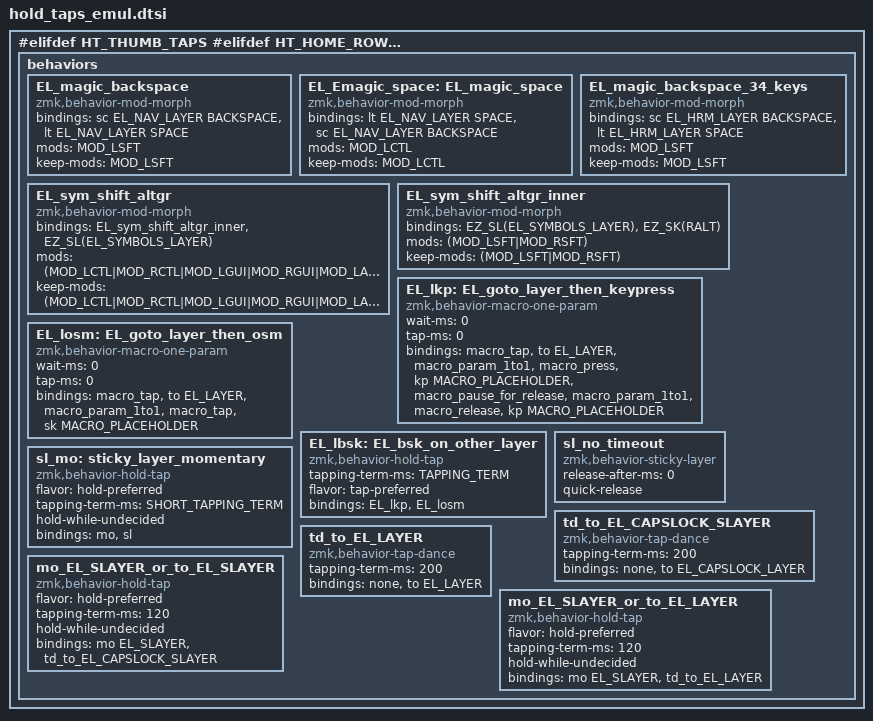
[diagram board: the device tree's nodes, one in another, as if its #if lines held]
#include <behaviors.dtsi>
#include <dt-bindings/zmk/keys.h>

// clang-format off
#define EL_LAYER           8
#define EL_CAPSLOCK_LAYER  9
#define EL_SLAYER         10
#define EL_1DK_LAYER      11
#define EL_S1DK_LAYER     12
#define EL_NUM_LOCK_LAYER 13
#define EL_SYMBOLS_LAYER  14
#define EL_SSYMBOLS_LAYER 15
#define EL_VIM_NAV_LAYER  16
#define EL_NUM_NAV_LAYER  17
#define EL_SNUM_NAV_LAYER 18
#define EL_NUM_ROW_LAYER  19

#define GAME_LAYER        20
#define G_NUM_ROW_LAYER   21
#define G_NAVNUM_LAYER    22
#define G_SYMBOLS_LAYER   23
#define FUNCTION_LAYER    24
#define BT                25

/**
 * Home Rew
 */

#if defined HT_HOME_ROW_MODS || defined HT_TWO_THUMB_KEYS
//  #define HRM_S &hrm LGUI S
  #define HRM_FR_A &hrm LSHIFT FR_A
  #define HRM_E &hrm LCTL E
  #define HRM_N &hrm LALT N
  #define HRM_R &hrm LALT R
  #define HRM_T &hrm RCTL T
  #define HRM_I &hrm RGUI I
  #define HRM_FR_U &hrm LSHIFT FR_U
  //test for gaming layer --TODO
  #define HRM_GA &hrm LSHIFT A
  #define HRM_GZ &hrm LCTL   Z
#else
//  #define HRM_S &kp S
  #define HRM_FR_A &kp FR_A
  #define HRM_E &kp E
  #define HRM_N &kp N
  #define HRM_R &kp R
  #define HRM_I &kp I
  #define HRM_T &kp T
  #define HRM_FR_U &kp FR_U
#endif

/**
 * Thumb Keys
 */

#ifdef VIM_NAVIGATION
  #define EL_NAV_LAYER EL_VIM_NAV_LAYER
  #define EL_NUM_LAYER EL_NUM_ROW_LAYER
  #define EL_HRM_LAYER EL_NUM_ROW_LAYER
  #define EL_S34_LAYER EL_NUM_ROW_LAYER
//  #define REACH_TAP ESCAPE
#else
  #define EL_NAV_LAYER EL_NUM_NAV_LAYER
  #define EL_NUM_LAYER EL_NUM_NAV_LAYER
  #define EL_HRM_LAYER FUNCTION_LAYER
  #define EL_S34_LAYER EL_NUM_NAV_LAYER
 // #define REACH_TAP TAB
#endif

#if defined HT_TWO_THUMB_KEYS && !defined VIM_NAVIGATION
  #define EL_SYM_NUM_LAYER &sc EL_NUM_NAV_LAYER CAPSLOCK
#else
  #define EL_SYM_NUM_LAYER &EZ_SL(EL_NUM_LAYER)
#endif

#ifdef LHAND_SPACE
  #define EL_LTHUMB_TT  &hrm LCTL SPACE
  #define EL_RTHUMB_TT  &EL_magic_backspace
  #define EL_LTHUMB_HRM &lt EL_NAV_LAYER SPACE
  #define EL_RTHUMB_HRM &EL_magic_backspace
  #define EL_LTHUMB_S34 &lt EL_NAV_LAYER SPACE
  #define EL_RTHUMB_S34 &EL_magic_backspace_34_keys
 // #define EL_SHIFTED_LTHUMB_HRM &lt EL_SNUM_NAV_LAYER SPACE
  #define EL_SHIFTED_RTHUMB_HRM &sc EL_SNUM_NAV_LAYER BACKSPACE
#else
  #define EL_LTHUMB_TT  &mt LCTL BACKSPACE
  #define EL_RTHUMB_TT  &EL_magic_space
  #define EL_LTHUMB_HRM &sc EL_NAV_LAYER BACKSPACE
  #define EL_RTHUMB_HRM &lt EL_NAV_LAYER SPACE
  #define EL_LTHUMB_S34 &sc EL_NAV_LAYER BACKSPACE
  #define EL_RTHUMB_S34 &lt EL_S34_LAYER SPACE
 // #define EL_SHIFTED_LTHUMB_HRM &sc EL_SNUM_NAV_LAYER BACKSPACE
  #define EL_SHIFTED_RTHUMB_HRM &lt EL_SNUM_NAV_LAYER LS(SPACE)
  #define EL_SHIFTED_LTHUMB_HRM &lt EL_NUM_NAV_LAYER BACKSPACE
// le pouce gauche nav_num a le bon comportement (utilsable uniquement en capslock, renvoit vers num_nav non shifté)
// le pouce droit nav_num en shift est OK, mais not_ok en capslock, car on renvoit vers le layer num_nav shifté.
// Ce n’est pas idéal à cause de la partie NAV qui du coup est shifté quand on capslock
// Pour avoir le bon comportement, il faut ajouter (encore) un nouveau layer dédié
// pour capslock… capslock-ergol-layer (EL_CAPSLOCK_LAYER)

// donc:
// TODO: ajouter un layer capslock dont les touches de pouces renvoient vers les layers
//       non shiftés.

#endif

#ifdef HT_NONE
  #define EL_LTHUMB_TUCK   &kp LALT
  #define EL_LTHUMB_HOME   &kp LCTL
  #define EL_LTHUMB_REACH  &kp LGUI
  #define EL_RTHUMB_REACH  &mo EL_NAV_LAYER
  #define EL_RTHUMB_HOME   &kp SPACE
  #define EL_RTHUMB_TUCK   &mo EL_SYMBOLS_LAYER
#elifdef HT_THUMB_TAPS
  #define EL_LTHUMB_TUCK   &EZ_SL(EL_SLAYER)
  #define EL_LTHUMB_HOME   EL_LTHUMB_TT
  #define EL_LTHUMB_REACH  &mt LGUI REACH_TAP
  #define EL_RTHUMB_REACH  &mt LALT ENTER
  #define EL_RTHUMB_HOME   EL_RTHUMB_TT
  #define EL_RTHUMB_TUCK   &EL_sym_shift_altgr
#elifdef HT_HOME_ROW_MODS
  //#define EL_LTHUMB_TUCK   &EZ_SL(EL_SLAYER)
  //#define EL_LTHUMB_TUCK   &EL_dbltap_shift
  #define EL_LTHUMB_TUCK   &mo_EL_SLAYER_or_to_EL_SLAYER
  #define EL_LTHUMB_HOME   EL_LTHUMB_HRM
  #define EL_LTHUMB_REACH  &sc EL_HRM_LAYER REACH_TAP
  #define EL_RTHUMB_REACH  &sc EL_HRM_LAYER ENTER
  #define EL_RTHUMB_HOME   EL_RTHUMB_HRM
  #define EL_RTHUMB_TUCK   &EL_sym_shift_altgr

  #define EL_SHIFTED_LTHUMB_TUCK  &none //&td_to EL_LAYER
  #define EL_SHIFTED_LTHUMB_HOME  EL_SHIFTED_LTHUMB_HRM
 // #define EL_SHIFTED_LTHUMB_REACH &td_to_EL_LAYER

  #define EL_CAPSLOCK_LTHUMB_TUCK &mo_EL_SLAYER_or_to_EL_LAYER

  #define EL_SHIFTED_RTHUMB_REACH &kp LS(ENTER)
  #define EL_SHIFTED_RTHUMB_HOME  EL_SHIFTED_RTHUMB_HRM
  #define EL_SHIFED_RTHUMB_TUCK &sl EL_SSYMBOLS_LAYER

  #define EL_NAVNUM_RTHUMB_TUCK  &sl_mo EL_SNUM_NAV_LAYER EL_SNUM_NAV_LAYER
#elifdef HT_TWO_THUMB_KEYS
  #define EL_LTHUMB_TUCK   &mt LSHIFT REACH_TAP
  #define EL_LTHUMB_HOME   EL_LTHUMB_S34
  #define EL_LTHUMB_REACH  EL_LTHUMB_TUCK
  #define EL_RTHUMB_REACH  &sc EL_SYMBOLS_LAYER ENTER
  #define EL_RTHUMB_HOME   EL_RTHUMB_S34
  #define EL_RTHUMB_TUCK   EL_RTHUMB_REACH
#endif

#define EL_X_UNDO  &kp CMD(W)
#define EL_X_CUT   &kp CMD(X)
#define EL_X_COPY  &kp CMD(C)
#define EL_X_PASTE &kp CMD(V)
#define EL_X_REDO  &kp CMD(Y)

#define EL_X_CLOSE &kp CMD(Z)
#define EL_X_SAVE  &kp CMD(S)
#define EL_X_ALL   &kp CMD(Q)

//#define EZ_SL(layer)  bsl (layer) (layer)
//#define EZ_SK(mod)    bsk (mod) (mod)
//#define EL_EZ_LSK(mod)   lbsk (mod) (mod)

/ {
  behaviors {

    // mod-morphs to restore Shift+Space and Ctrl+Backspace for certain keymaps
    EL_magic_backspace: EL_magic_backspace {
      compatible = "zmk,behavior-mod-morph";
      #binding-cells = <0>;
      bindings = <&sc EL_NAV_LAYER BACKSPACE>, <&lt EL_NAV_LAYER SPACE>;
      mods      = <MOD_LSFT>;
      keep-mods = <MOD_LSFT>;
    };
    EL_Emagic_space: EL_magic_space {
      compatible = "zmk,behavior-mod-morph";
      #binding-cells = <0>;
      bindings = <&lt EL_NAV_LAYER SPACE>, <&sc EL_NAV_LAYER BACKSPACE>;
      mods      = <MOD_LCTL>;
      keep-mods = <MOD_LCTL>;
    };
    EL_magic_backspace_34_keys: EL_magic_backspace_34_keys {
      compatible = "zmk,behavior-mod-morph";
      #binding-cells = <0>;
      bindings = <&sc EL_HRM_LAYER BACKSPACE>, <&lt EL_HRM_LAYER SPACE>;
      mods      = <MOD_LSFT>;
      keep-mods = <MOD_LSFT>;
    };

  // XXX this whole AltGr section should probably be inside the `behaviors` branch
  // AltGr support

  // Sym becomes Shift+AltGr when combined with exclusively Shift
  EL_sym_shift_altgr: EL_sym_shift_altgr {
    compatible = "zmk,behavior-mod-morph";
    #binding-cells = <0>;
    bindings = <&EL_sym_shift_altgr_inner>, <&EZ_SL(EL_SYMBOLS_LAYER)>;
    mods      = <(MOD_LCTL|MOD_RCTL|MOD_LGUI|MOD_RGUI|MOD_LALT)>;
    keep-mods = <(MOD_LCTL|MOD_RCTL|MOD_LGUI|MOD_RGUI|MOD_LALT)>;
  };
  EL_sym_shift_altgr_inner: EL_sym_shift_altgr_inner {
    compatible = "zmk,behavior-mod-morph";
    #binding-cells = <0>;
    bindings = <&EZ_SL(EL_SYMBOLS_LAYER)>, <&EZ_SK(RALT)>;
    mods      = <(MOD_LSFT|MOD_RSFT)>;
    keep-mods = <(MOD_LSFT|MOD_RSFT)>;
  };

  // go to base layer and press mod

  EL_lkp: EL_goto_layer_then_keypress {
    compatible = "zmk,behavior-macro-one-param";
    wait-ms = <0>;
    tap-ms = <0>;
    #binding-cells = <1>;
    bindings =
      <&macro_tap &to EL_LAYER>,
      <&macro_param_1to1>,
      <&macro_press &kp MACRO_PLACEHOLDER>,
      <&macro_pause_for_release>,
      <&macro_param_1to1>,
      <&macro_release &kp MACRO_PLACEHOLDER>;
  };
  EL_losm: EL_goto_layer_then_osm {
    compatible = "zmk,behavior-macro-one-param";
    wait-ms = <0>;
    tap-ms = <0>;
    #binding-cells = <1>;
    bindings =
      <&macro_tap &to EL_LAYER>,
      <&macro_param_1to1>,
      <&macro_tap &sk MACRO_PLACEHOLDER>;
  };
  EL_lbsk: EL_bsk_on_other_layer {
    compatible = "zmk,behavior-hold-tap";
    #binding-cells = <2>;
    tapping-term-ms = <TAPPING_TERM>;
    flavor = "tap-preferred";
    bindings = <&EL_lkp>, <&EL_losm>;
  };
// pour émuler la touche morte, un sticky layer sans timeout
  sl_no_timeout: sl_no_timeout {
    compatible = "zmk,behavior-sticky-layer";
    #binding-cells = <1>;
    release-after-ms = <0>;
    quick-release;      // optionnel
  };
// pour ajout shift depuis nav
// probablement à améliorer
// À renommer pour être cohérent avec le reste
// reste à implémenter le double shift=capslock
  sl_mo: sticky_layer_momentary {
    compatible = "zmk,behavior-hold-tap";
    #binding-cells = <2>;
    flavor = "hold-preferred";
    tapping-term-ms = <SHORT_TAPPING_TERM>;
    //tapping-term-ms = <120>;
    hold-while-undecided;
    bindings = <&mo>, <&sl>;
  };
// pour ajout shift - double tap/caplock
//  sl_mo_EL_SLAYER: sl_mo_EL_SLAYER {
//    compatible = "zmk,behavior-hold-tap";
//    #binding-cells = <0>;
//    flavor = "balanced";
//    tapping-term-ms = <200>;
//    quick-tap-ms = <200>;
//    bindings = <&mo>, <&sl>;
//  };
//  EL_dbltap_shift: EL_dbltap_shift {
//    compatible = "zmk,behavior-tap-dance";
//    #binding-cells = <0>;
//    tapping-term-ms = <TAPPING_TERM>;
    //tapping-term-ms = <100>;
//    bindings = <&sl_mo EL_SLAYER EL_SLAYER>, <&to EL_SLAYER >;
//  };
//  td_to_EL_LAYER: td_to_EL_LAYER {
//    compatible = "zmk,behavior-tap-dance";
//    #binding-cells = <0>;
//    tapping-term-ms = <TAPPING_TERM>;
//    bindings = <&none>, <&to EL_LAYER>;
//        };


  td_to_EL_CAPSLOCK_SLAYER: td_to_EL_CAPSLOCK_SLAYER {
    compatible = "zmk,behavior-tap-dance";
    #binding-cells = <0>;
    tapping-term-ms = <200>;
    bindings = <&none>, <&to EL_CAPSLOCK_LAYER>;
  };

  mo_EL_SLAYER_or_to_EL_SLAYER: mo_EL_SLAYER_or_to_EL_SLAYER{
    compatible = "zmk,behavior-hold-tap";
    #binding-cells = <0>;
    flavor = "hold-preferred";
    tapping-term-ms = <120>;
    hold-while-undecided;
    bindings = <&mo EL_SLAYER>, <&td_to_EL_CAPSLOCK_SLAYER>;
  };

  td_to_EL_LAYER: td_to_EL_LAYER {
    compatible = "zmk,behavior-tap-dance";
    #binding-cells = <0>;
    tapping-term-ms = <200>;
    bindings = <&none>, <&to EL_LAYER>;
  };

    mo_EL_SLAYER_or_to_EL_LAYER: mo_EL_SLAYER_or_to_EL_LAYER{
    compatible = "zmk,behavior-hold-tap";
    #binding-cells = <0>;
    flavor = "hold-preferred";
    tapping-term-ms = <120>;
    hold-while-undecided;
    bindings = <&mo EL_SLAYER>, <&td_to_EL_LAYER>;
  };


 };
};
